# ESP32-S31 register map
Vendor: ESPRESSIF SYSTEMS (SHANGHAI) CO., LTD.; Series: ESP32 S-Series; File version: 1
CPU: RV32IMAFC r0p0, little endian, no MPU, FPU, 0 interrupt priority bits
Address unit: 32 bits
Registers are 32-bit, read-write, reset 0x0 unless marked. A register's access mark holds for its fields unless they carry their own. Offsets are from the block's base; [hi:lo] are bit positions.

## USB_OTG_HS (part 1 of 5) — USB_OTG_HS Peripheral
Base 0x20300000
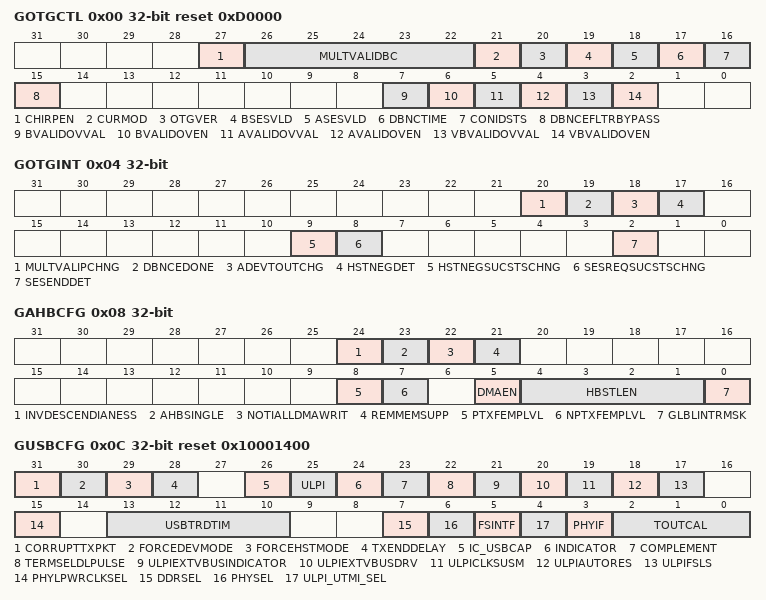
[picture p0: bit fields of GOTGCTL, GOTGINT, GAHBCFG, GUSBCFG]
0x00 GOTGCTL access per field reset 0xD0000 — The OTG Control and Status register controls the behavior and reflects the status of the OTG function of the controller.
  [27] CHIRPEN rw — Mode: Device Only This bit when programmed to 1'b1 results in the core asserting chirp_on before sending an actual Chirp K signal on USB. This bit is present only if OTG_BC_SUPPORT = 1.If OTG_BC_SUPPORT!=1, this bit is a reserved bit. Do not set this bit when core is operating in HSIC mode because HSIC always operates at High Speed and High speed chirp is not used
  [26:22] MULTVALIDBC ro — Mode: Host and Device Multi Valued ID pin (MultValIdBC) Battery Charger ACA inputs in the following order: - Bit 26: rid_float. - Bit 25: rid_gnd - Bit 24: rid_a - Bit 23: rid_b - Bit 22: rid_c
  [21] CURMOD ro — Current Mode of Operation (CurMod) Mode: Host and Device Indicates the current mode. - 1'b0: Device mode - 1'b1: Host mode Reset: - 1'b1 in Host-only mode (OTG_MODE=5 or 6) - 1'b0 in all other configurations Note: The reset value of this register field can be read only after the PHY clock is stable, or if IDDIG_FILTER is enabled, wait for the filter timer to expire to read the correct reset value which ever event is later.
  [20] OTGVER rw — OTG Version (OTGVer) Indicates the OTG revision. - 1'b0: OTG Version 1.3. In this version the core supports Data line pulsing and VBus pulsing for SRP. - 1'b1: OTG Version 2.0. In this version the core supports only Data line pulsing for SRP.
  [19] BSESVLD ro — Mode: Device only B-Session Valid (BSesVld) Indicates the Device mode transceiver status. - 1'b0: B-session is not valid. - 1'b1: B-session is valid. In OTG mode, you can use this bit to determine if the device is connected or disconnected. Note: - If you do not enable OTG features (such as SRP and HNP), the read reset value will be 1.The vbus assigns the values internally for non- SRP or non-HNP configurations. - In case of OTG_MODE=0, the reset value of this bit is 1'b0. - The reset value of this register field can be read only after the PHY clock is stable, or if IDDIG_FILTER is enabled, wait for the filter timer to expire to read the correct reset value which ever event is later.
  [18] ASESVLD ro — Mode: Host only A-Session Valid (ASesVld) Indicates the Host mode transceiver status. - 1'b0: A-session is not valid - 1'b1: A-session is valid Note: If you do not enabled OTG features (such as SRP and HNP), the read reset value will be 1. The vbus assigns the values internally for non-SRP or non-HNP configurations. In case of OTG_MODE=0, the reset value of this bit is 1'b0.
  [17] DBNCTIME ro — Mode: Host only Long/Short Debounce Time (DbncTime) Indicates the debounce time of a detected connection. - 1'b0: Long debounce time, used for physical connections (100 ms + 2.5 micro-sec) - 1'b1: Short debounce time, used for soft connections (2.5 micro-sec)
  [16] CONIDSTS ro — Mode: Host and Device Connector ID Status (ConIDSts) Indicates the connector ID status on a connect event. - 1'b0: The core is in A-Device mode. - 1'b1: The core is in B-Device mode. Note: The reset value of this register field can be read only after the PHY clock is stable, or if IDDIG_FILTER is enabled, wait for the filter timer to expire to read the correct reset value which ever event is later. Reset: - 1'b0: in host only mode (OTG_MODE = 5 or 6) - 1'b1: in all other configurations
  [15] DBNCEFLTRBYPASS rw — Mode: Host and Device Debounce Filter Bypass Bypass Debounce filters for avalid, bvalid, vbusvalid, sessend, iddig signals when enabled. - 1'b0: Disabled - 1'b1: Enabled Note: This register bit is valid only when debounce filters are present in core.
  [7] BVALIDOVVAL rw — Mode: Device only B-Peripheral Session Valid OverrideValue (BvalidOvVal) This bit is used to set Override value for Bvalid signal when GOTGCTL.BvalidOvEn is set. - 1'b0 : Bvalid value is 1'b0 when GOTGCTL.BvalidOvEn =1 - 1'b1 : Bvalid value is 1'b1 when GOTGCTL.BvalidOvEn =1
  [6] BVALIDOVEN rw — Mode: Device only B-Peripheral Session Valid Override Value (BvalidOvEn) This bit is used to enable/disable the software to override the Bvalid signal using the GOTGCTL.BvalidOvVal. - 1'b1 : Internally Bvalid received from the PHY is overridden with GOTGCTL.BvalidOvVal. - 1'b0 : Override is disabled and bvalid signal from the respective PHY selected is used internally by the force
  [5] AVALIDOVVAL rw — Mode: Host only A-Peripheral Session Valid OverrideValue (AvalidOvVal) This bit is used to set Override value for Avalid signal when GOTGCTL.AvalidOvEn is set. - 1'b0 : Avalid value is 1'b0 when GOTGCTL.AvalidOvEn =1 - 1'b1 : Avalid value is 1'b1 when GOTGCTL.AvalidOvEn =1
  [4] AVALIDOVEN rw — Mode: Host only A-Peripheral Session Valid Override Enable (AvalidOvEn) This bit is used to enable/disable the software to override the Avalid signal using the GOTGCTL.AvalidOvVal. - 1'b1: Internally Avalid received from the PHY is overridden with GOTGCTL.AvalidOvVal. - 1'b0: Override is disabled and avalid signal from the respective PHY selected is used internally by the core
  [3] VBVALIDOVVAL rw — Mode: Host only VBUS Valid OverrideValue (VbvalidOvVal) This bit is used to set Override value for vbusvalid signal when GOTGCTL.VbvalidOvEn is set. - 1'b0 : vbusvalid value is 1'b0 when GOTGCTL.VbvalidOvEn =1 - 1'b1 : vbusvalid value is 1'b1 when GOTGCTL.VbvalidOvEn =1
  [2] VBVALIDOVEN rw — Mode: Host only VBUS Valid Override Enable (VbvalidOvEn) This bit is used to enable/disable the software to override the Bvalid signal using the GOTGCTL.VbvalidOvVal. - 1'b1 : Internally Bvalid received from the PHY is overridden with GOTGCTL.VbvalidOvVal. - 1'b0 : Override is disabled and bvalid signal from the respective PHY selected is used internally by the controller.
0x04 GOTGINT — The application reads this register whenever there is an OTG interrupt and clears the bits in this register to clear the OTG interrupt.
  [20] MULTVALIPCHNG — This bit when set indicates that there is a change in the value of at least one ACA pin value. This bit is present only if OTG_BC_SUPPORT=1, otherwise it is reserved.
  [19] DBNCEDONE — Mode: Host only Debounce Done (DbnceDone) The core sets this bit when the debounce is completed after the device connect. The application can start driving USB reset after seeing this interrupt. This bit is only valid when the HNP Capable or SRP Capable bit is SET in the Core USB Configuration register (GUSBCFG.HNPCap or GUSBCFG.SRPCap, respectively). This bit can be set only by the core and the application must write 1 to clear it.
  [18] ADEVTOUTCHG — Mode: Host and Device A-Device Timeout Change (ADevTOUTChg) The core sets this bit to indicate that the A-device has timed out while waiting for the B-device to connect.This bit can be set only by the core and the application must write 1 to clear it.
  [17] HSTNEGDET — Mode:Host and Device Host Negotiation Detected (HstNegDet) The core sets this bit when it detects a host negotiation request on the USB. This bit can be set only by the core and the application must write 1 to clear it.
  [9] HSTNEGSUCSTSCHNG — Mode: Host and Device Host Negotiation Success Status Change (HstNegSucStsChng) The core sets this bit on the success or failure of a USB host negotiation request. The application must read the Host Negotiation Success bit of the OTG Control and Status register (GOTGCTL.HstNegScs) to check for success or failure. This bit can be set only by the core and the application must write 1 to clear it.
  [8] SESREQSUCSTSCHNG — Mode: Host and Device Session Request Success Status Change (SesReqSucStsChng) The core sets this bit on the success or failure of a session request. The application must read the Session Request Success bit in the OTG Control and Status register (GOTGCTL.SesReqScs) to check for success or failure. This bit can be set only by the core and the application must write 1 to clear it.
  [2] SESENDDET — Mode: Host and Device Session End Detected (SesEndDet) The controller sets this bit when the utmiotg_bvalid signal is deasserted. This bit can be set only by the core and the application must write 1 to clear it.
0x08 GAHBCFG — This register can be used to configure the core after power-on or a change in mode. This register mainly contains AHB system-related configuration parameters. Do not change this register after the initial programming. The application must program this register before starting any transactions on either the AHB or the USB.
  [24] INVDESCENDIANESS — Mode: Host and Device Invert Descriptor Endianess (InvDescEndianess) - 1'b0: Descriptor Endianness is same as AHB Master Endianness. - 1'b1: -- If the AHB Master endianness is Big Endian, the Descriptor Endianness is Little Endian. -- If the AHB Master endianness is Little Endian, the Descriptor Endianness is Big Endian.
  [23] AHBSINGLE — Mode: Host and Device AHB Single Support (AHBSingle) This bit when programmed supports Single transfers for the remaining data in a transfer when the core is operating in DMA mode. - 1'b0: The remaining data in the transfer is sent using INCR burst size. - 1'b1: The remaining data in the transfer is sent using Single burst size. Note: If this feature is enabled, the AHB RETRY and SPLIT transfers still have INCR burst type. Enable this feature when the AHB Slave connected to the core does not support INCR burst (and when Split, and Retry transactions are not being used in the bus).
  [22] NOTIALLDMAWRIT — Mode: Host and Device Notify All DMA Write Transactions (NotiAllDmaWrit) This bit is programmed to enable the System DMA Done functionality for all the DMA write Transactions corresponding to the Channel/Endpoint. This bit is valid only when GAHBCFG.RemMemSupp is set to 1. - GAHBCFG.NotiAllDmaWrit = 1 The core asserts int_dma_req for all the DMA write transactions on the AHB interface along with int_dma_done, chep_last_transact and chep_number signal informations. The core waits for sys_dma_done signal for all the DMA write transactions in order to complete the transfer of a particular Channel/Endpoint. - GAHBCFG.NotiAllDmaWrit = 0 The core asserts int_dma_req signal only for the last transaction of DMA write transfer corresponding to a particular Channel/Endpoint. Similarly, the core waits for sys_dma_done signal only for that transaction of DMA write to complete the transfer of a particular Channel/Endpoint.
  [21] REMMEMSUPP — Mode: Host and Device Remote Memory Support (RemMemSupp) This bit is programmed to enable the functionality to wait for the system DMA Done Signal for the DMA Write Transfers. - GAHBCFG.RemMemSupp=1 The int_dma_req output signal is asserted when the DMA starts write transfer to the external memory. When the core is done with the Transfers it asserts int_dma_done signal to flag the completion of DMA writes from the controller. The core then waits for sys_dma_done signal from the system to proceed further and complete the Data Transfer corresponding to a particular Channel/Endpoint. - GAHBCFG.RemMemSupp=0 The int_dma_req and int_dma_done signals are not asserted and the core proceeds with the assertion of the XferComp interrupt as soon as the DMA write transfer is done at the Core Boundary and it does not wait for the sys_dma_done signal to complete the DATA transfers.
  [8] PTXFEMPLVL — Mode: Host only Periodic TxFIFO Empty Level (PTxFEmpLvl) Indicates when the Periodic TxFIFO Empty Interrupt bit in the Core Interrupt register (GINTSTS.PTxFEmp) is triggered. This bit is used only in Slave mode. - 1'b0: GINTSTS.PTxFEmp interrupt indicates that the Periodic TxFIFO is half empty - 1'b1: GINTSTS.PTxFEmp interrupt indicates that the Periodic TxFIFO is completely empty
  [7] NPTXFEMPLVL — Mode: Host and device Non-Periodic TxFIFO Empty Level (NPTxFEmpLvl) This bit is used only in Slave mode. In host mode and with Shared FIFO with device mode, this bit indicates when the Non-Periodic TxFIFO Empty Interrupt bit in the Core Interrupt register (GINTSTS.NPTxFEmp) is triggered. With dedicated FIFO in device mode, this bit indicates when IN endpoint Transmit FIFO empty interrupt (DIEPINTn.TxFEmp) is triggered. Host mode and with Shared FIFO with device mode: - 1'b0: GINTSTS.NPTxFEmp interrupt indicates that the Non-Periodic TxFIFO is half empty - 1'b1: GINTSTS.NPTxFEmp interrupt indicates that the Non-Periodic TxFIFO is completely empty Dedicated FIFO in device mode: - 1'b0: DIEPINTn.TxFEmp interrupt indicates that the IN Endpoint TxFIFO is half empty - 1'b1: DIEPINTn.TxFEmp interrupt indicates that the IN Endpoint TxFIFO is completely empty
  [5] DMAEN — Mode: Host and device DMA Enable (DMAEn) This bit is always 0 when Slave-Only mode has been selected. Reset: 1'b0
  [4:1] HBSTLEN — Mode: Host and device Burst Length/Type (HBstLen) This field is used in both External and Internal DMA modes. In External DMA mode, these bits appear on dma_burst[3:0] ports, which can be used by an external wrapper to interface the External DMA Controller interface to Synopsys DW_ahb_dmac or ARM PrimeCell. External DMA Mode defines the DMA burst length in terms of 32-bit words: - 4'b0000: 1 word - 4'b0001: 4 words - 4'b0010: 8 words - 4'b0011: 16 words - 4'b0100: 32 words - 4'b0101: 64 words - 4'b0110: 128 words - 4'b0111: 256 words - Others: Reserved Internal DMA Mode AHB Master burst type: - 4'b0000 Single - 4'b0001 INCR - 4'b0011 INCR4 - 4'b0101 INCR8 - 4'b0111 INCR16 - Others: Reserved
  [0] GLBLINTRMSK — Mode: Host and device Global Interrupt Mask (GlblIntrMsk) The application uses this bit to mask or unmask the interrupt line assertion to itself. Irrespective of this bit's setting, the interrupt status registers are updated by the controller.
0x0C GUSBCFG access per field reset 0x10001400 — This register can be used to configure the core after power-on or when changing to Host mode or Device mode. It contains USB and USB-PHY related configuration parameters. The application must program this register before starting any transactions on either the AHB or the USB. If you are using the HSIC interface, HSIC PHY must be in reset while programming this register. Do not make changes to this register after the initial programming.
  [31] CORRUPTTXPKT rw — Mode: Host and device Corrupt Tx packet (CorruptTxPkt) This bit is for debug purposes only. Never Set this bit to 1. The application must always write 1'b0 to this bit.
  [30] FORCEDEVMODE rw — Mode:Host and device Force Device Mode (ForceDevMode) Writing a 1 to this bit forces the controller to device mode irrespective of utmiotg_iddig input pin. - 1'b0 : Normal Mode. - 1'b1 : Force Device Mode. After setting the force bit, the application must wait at least 25 ms before the change to take effect. When the simulation is in scale down mode, waiting for 500 micro sec is sufficient. This bit is valid only when OTG_MODE = 0, 1 or 2. In all other cases, this bit reads 0.
  [29] FORCEHSTMODE rw — Mode: Host and device Force Host Mode (ForceHstMode) Writing a 1 to this bit forces the core to host mode irrespective of utmiotg_iddig input pin. - 1'b0 : Normal Mode. - 1'b1 : Force Host Mode. After setting the force bit, the application must wait at least 25 ms before the change to take effect. When the simulation is in scale down mode, waiting for 500 micro sec is sufficient. This bit is valid only when OTG_MODE = 0, 1 or 2. In all other cases, this bit reads 0.
  [28] TXENDDELAY rw — Mode: Device only Tx End Delay (TxEndDelay) Setting this bit to 1'b1 enables the controller to follow the TxEndDelay timings as per UTMI+ specification 1.05 section 4.1.5 for opmode signal during remote wakeup. - 1'b0 : Normal Mode. - 1'b1 : Tx End delay. The default value of this field is 1'b1 and it is not recommended to program it to 1'b0. The option to set it to 1'b0 (Normal Mode) is present only for debug purpose.
  [26] IC_USBCAP ro — Mode: Host and Device IC_USB-Capable (IC_USBCap) The application uses this bit to control the core's IC_USB capabilities. - 1'b0: IC_USB PHY Interface is not selected. - 1'b1: IC_USB PHY Interface is selected. This bit is writable only if OTG_ENABLE_IC_USB=1 and OTG_FSPHY_INTERFACE!=0. The reset value depends on the configuration parameter OTG_SELECT_IC_USB when OTG_ENABLE_IC_USB = 1. In all other cases, this bit is set to 1'b0 and the bit is read only.
  [25] ULPI rw — Mode: Host only ULPI Interface Protect Disable Controls circuitry built into the PHY for protecting the ULPI interface when the link tri-states STP and data. Any pull-ups or pull-downs employed by this feature can be disabled. For more information, refer to the ULPI Specification. - 1'b0: Enables the interface protect circuit - 1'b1: Disables the interface protect circuit
  [24] INDICATOR rw — Mode: Host only Indicator Pass Through Controls wether the Complement Output is qualified with the Internal Vbus Valid comparator before being used in the Vbus State in the RX CMD. For more information, refer to the ULPI Specification. - 1'b0: Complement Output signal is qualified with the Internal VbusValid comparator. - 1'b1: Complement Output signal is not qualified with the Internal VbusValid comparator. This bit is reserved and read-only when OTG_HSPHY_INTERFACE is set to 0 or 1.
  [23] COMPLEMENT rw — Mode: Host only Indicator Complement Controls the PHY to invert the ExternalVbusIndicator input signal, generating the Complement Output. For more information, refer to the ULPI Specification. - 1'b0: PHY does not invert ExternalVbusIndicator signal - 1'b1: PHY does invert ExternalVbusIndicator signal This bit is reserved and read-only when OTG_HSPHY_INTERFACE is set to 0 or 1.
  [22] TERMSELDLPULSE rw — Mode: Device only TermSel DLine Pulsing Selection (TermSelDLPulse) This bit selects utmi_termselect to drive data line pulse during SRP. - 1'b0: Data line pulsing using utmi_txvalid (Default). - 1'b1: Data line pulsing using utmi_termsel.
  [21] ULPIEXTVBUSINDICATOR rw — Mode: Host only ULPI External VBUS Indicator (ULPIExtVbusIndicator) This bit indicates to the ULPI PHY to use an external VBUS overcurrent indicator. - 1'b0: PHY uses internal VBUS valid comparator. - 1'b1: PHY uses external VBUS valid comparator.
  [20] ULPIEXTVBUSDRV rw — Mode: Host only ULPI External VBUS Drive (ULPIExtVbusDrv) This bit selects between internal or external supply to drive 5V on VBUS, in ULPI PHY. - 1'b0: PHY drives VBUS using internal charge pump (Default). - 1'b1: PHY drives VBUS using external supply.
  [19] ULPICLKSUSM rw — Mode: Host and Device ULPI Clock SuspendM (ULPIClkSusM) This bit sets the ClockSuspendM bit in the Interface Control register on the ULPI PHY. This bit applies only in serial or carkit modes. - 1'b0: PHY powers down internal clock during suspend. - 1'b1: PHY does not power down internal clock.
  [18] ULPIAUTORES rw — Mode: Host and Device ULPI Auto Resume (ULPIAutoRes) This bit sets the AutoResume bit in the Interface Control register on the ULPI PHY. - 1'b0: PHY does not use AutoResume feature. - 1'b1: PHY uses AutoResume feature.
  [17] ULPIFSLS rw — Mode: Host and Device ULPI FS/LS Select (ULPIFsLs) The application uses this bit to select the FS/LS serial interface for the ULPI PHY. This bit is valid only when the FS serial transceiver is selected on the ULPI PHY. - 1'b0: ULPI interface - 1'b1: ULPI FS/LS serial interface Note: Before setting this bit, the application needs to ensure that GUSBCFG.ULPI_UTMI_SEL = 1'b1.
  [15] PHYLPWRCLKSEL rw — PHY Low-Power Clock Select (PhyLPwrClkSel) Mode: Host and Device Selects either 480-MHz or 48-MHz (low-power) PHY mode. In FS and LS modes, the PHY can usually operate on a 48-MHz clock to save power. - 1'b0: 480-MHz Internal PLL clock - 1'b1: 48-MHz External Clock In 480 MHz mode, the UTMI interface operates at either 60 or 30-MHz, depending upon whether 8- or 16-bit data width is selected. In 48-MHz mode, the UTMI interface operates at 48 MHz in FS mode and at either 48 or 6 MHz in LS mode (depending on the PHY vendor). This bit drives the utmi_fsls_low_power core output signal, and is valid only for UTMI+ PHYs.
  [13:10] USBTRDTIM rw — Mode: Device only USB Turnaround Time (USBTrdTim) Sets the turnaround time in PHY clocks. Specifies the response time for a MAC request to the Packet FIFO Controller (PFC) to fetch data from the DFIFO (SPRAM). This must be programmed to - 4'h5 : When the MAC interface is 16-bit UTMI+ - 4'h9 : When the MAC interface is 8-bit UTMI+ Note:Refer to Programming Guide Section Choosing the Value of GUSBCFG.USBTrdTim for the turnaround time calculation. During the AHB Clock Frequency selection, it is recommended to consider mis-sampling into account for USBTrdTim. USB turnaround time is critical for certification where long cables and 5-Hubs are used. If you need the AHB to run at less than 30 MHz (or less than 42MHz when operating in 16-bit UTMI mode in HS speed), and if USB turnaround time is not critical, these bits can be programmed to a larger value.
  [7] DDRSEL rw — Mode: Host and Device ULPI DDR Select (DDRSel) The application uses this bit to select a Single Data Rate (SDR) or Double Data Rate (DDR) or ULPI interface. - 1'b0: Single Data Rate ULPI Interface, with 8-bit-wide data bus - 1'b1: Double Data Rate ULPI Interface, with 4-bit-wide data bus
  [6] PHYSEL rw — PHYSel Mode: Host and Device USB 2.0 High-Speed PHY or USB 1.1 Full-Speed Serial Transceiver Select (PHYSel) The application uses this bit to select either a high-speed UTMI+ or ULPI PHY, or a full-speed transceiver. - 1'b0: USB 2.0 high-speed UTMI+ or ULPI PHY - 1'b1: USB 1.1 full-speed serial transceiver If a USB 1.1 Full-Speed Serial Transceiver interface was not selected in, this bit is always 0, with Write Only access. If a high-speed PHY interface was not selected in, this bit is always 1, with Write Only access. If both interface types were selected (parameters have non-zero values), the application uses this bit to select which interface is active, and access is Read and Write.
  [5] FSINTF rw — Mode: Host and Device Full-Speed Serial Interface Select (FSIntf) The application uses this bit to select either a unidirectional or bidirectional USB 1.1 full-speed serial transceiver interface. - 1'b0: 6-pin unidirectional full-speed serial interface - 1'b1: 3-pin bidirectional full-speed serial interface If a USB 1.1 Full-Speed Serial Transceiver interface was not selected, this bit is always 0, with Write Only access. If a USB 1.1 FS interface was selected, Then the application can Set this bit to select between the 3- and 6-pin interfaces, and access is Read and Write. Note: For supporting the new 4-pin bi-directional interface, you need to select 6-pin unidirectional FS serial mode, and add an external control to convert it to a 4-pin interface.
  [4] ULPI_UTMI_SEL rw — Mode: Host and Device ULPI or UTMI+ Select (ULPI_UTMI_Sel) The application uses this bit to select either a UTMI+ interface or ULPI Interface. - 1'b0: UTMI+ Interface - 1'b1: ULPI Interface
  [3] PHYIF rw — Mode: Host and Device PHY Interface (PHYIf) The application uses this bit to configure the core to support a UTMI+ PHY with an 8- or 16-bit interface. When a ULPI PHY is chosen, this must be Set to 8-bit mode. - 1'b0: 8 bits - 1'b1: 16 bits This bit is writable only If UTMI+ and ULPI were selected. Otherwise, this bit returns the value for the power-on interface selected during configuration.
  [2:0] TOUTCAL rw — Mode: Host and Device HS/FS Timeout Calibration (TOutCal) The number of PHY clocks that the application programs in this field is added to the high-speed/full-speed interpacket timeout duration in the core to account for any additional delays introduced by the PHY. This can be required, because the delay introduced by the PHY in generating the linestate condition can vary from one PHY to another. The USB standard timeout value for high-speed operation is 736 to 816 (inclusive) bit times. The USB standard timeout value for full-speed operation is 16 to 18 (inclusive) bit times. The application must program this field based on the speed of enumeration. The number of bit times added per PHY clock are as follows: High-speed operation: - One 30-MHz PHY clock = 16 bit times - One 60-MHz PHY clock = 8 bit times Full-speed operation: - One 30-MHz PHY clock = 0.4 bit times - One 60-MHz PHY clock = 0.2 bit times - One 48-MHz PHY clock = 0.25 bit times
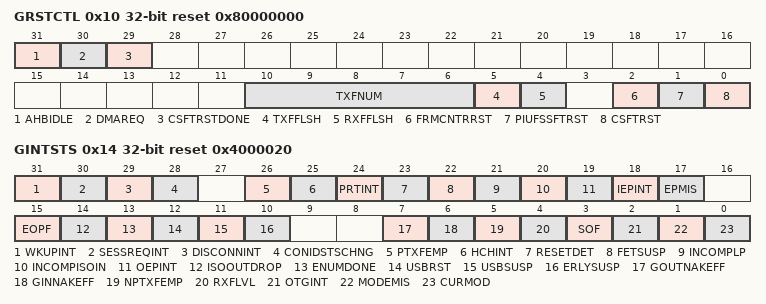
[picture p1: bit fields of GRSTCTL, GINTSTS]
0x10 GRSTCTL access per field reset 0x80000000 — The application uses this register to reset various hardware features inside the controller.
  [31] AHBIDLE ro — Mode: Host and Device AHB Master Idle (AHBIdle) Indicates that the AHB Master State Machine is in the IDLE condition.
  [30] DMAREQ ro — Mode: Host and Device DMA Request Signal (DMAReq) Indicates that the DMA request is in progress. Used for debug.
  [29] CSFTRSTDONE rw — Mode: Host and Device Core Soft Reset Done (CSftRstDone) The core sets this bit when all the necessary logic is reset in the core.This bit is cleared by the application along with GRSTCTL.CSftRst (bit 0)
  [10:6] TXFNUM rw — Mode: Host and Device TxFIFO Number (TxFNum) This is the FIFO number that must be flushed using the TxFIFO Flush bit. This field must not be changed until the core clears the TxFIFO Flush bit. - 5'h0: -- Non-periodic TxFIFO flush in Host mode -- Non-periodic TxFIFO flush in device mode when in shared FIFO operation -- Tx FIFO 0 flush in device mode when in dedicated FIFO mode - 5'h1: -- Periodic TxFIFO flush in Host mode -- Periodic TxFIFO 1 flush in Device mode when in shared FIFO operation -- TXFIFO 1 flush in device mode when in dedicated FIFO mode - 5'h2: -- Periodic TxFIFO 2 flush in Device mode when in shared FIFO operation -- TXFIFO 2 flush in device mode when in dedicated FIFO mode ... - 5'hF -- Periodic TxFIFO 15 flush in Device mode when in shared FIFO operation -- TXFIFO 15 flush in device mode when in dedicated FIFO mode - 5'h10: Flush all the transmit FIFOs in device or host mode
  [5] TXFFLSH rw — Mode: Host and Device TxFIFO Flush (TxFFlsh) This bit selectively flushes a single or all transmit FIFOs, but cannot do so If the core is in the midst of a transaction. The application must write this bit only after checking that the core is neither writing to the TxFIFO nor reading from the TxFIFO. Verify using these registers: - ReadNAK Effective Interrupt ensures the core is not reading from the FIFO - WriteGRSTCTL.AHBIdle ensures the core is not writing anything to the FIFO. Flushing is normally recommended when FIFOs are reconfigured or when switching between Shared FIFO and Dedicated Transmit FIFO operation. FIFO flushing is also recommended during device endpoint disable. The application must wait until the core clears this bit before performing any operations. This bit takes eight clocks to clear, using the slower clock of phy_clk or hclk.
  [4] RXFFLSH rw — Mode: Host and Device RxFIFO Flush (RxFFlsh) The application can flush the entire RxFIFO using this bit, but must first ensure that the core is not in the middle of a transaction. The application must only write to this bit after checking that the controller is neither reading from the RxFIFO nor writing to the RxFIFO. The application must wait until the bit is cleared before performing any other operations. This bit requires eight clocks (slowest of PHY or AHB clock) to clear.
  [2] FRMCNTRRST rw — Mode: Host only Host Frame Counter Reset (FrmCntrRst) The application writes this bit to reset the (micro)Frame number counter inside the core. When the (micro)Frame counter is reset, the subsequent SOF sent out by the core has a (micro)Frame number of 0. When application writes 1 to the bit, it might not be able to read back the value as it gets cleared by the core in a few clock cycles.
  [1] PIUFSSFTRST rw — Mode: Host and Device PIU FS Dedicated Controller Soft Reset (PIUFSSftRst) Resets the PIU FS Dedicated Controller All module state machines in FS Dedicated Controller of PIU are reset to the IDLE state. Used to reset the FS Dedicated controller in PIU in case of any PHY Errors like Loss of activity or Babble Error resulting in the PHY remaining in RX state for more than one frame boundary. This is a self clearing bit and core clears this bit after all the necessary logic is reset in the core.
  [0] CSFTRST rw — Mode: Host and Device Core Soft Reset (CSftRst) Resets the hclk and phy_clock domains as follows: - Clears the interrupts and all the CSR registers except the following register bits: -- PCGCCTL.RstPdwnModule -- PCGCCTL.GateHclk -- PCGCCTL.PwrClmp -- PCGCCTL.StopPPhyLPwrClkSelclk -- GUSBCFG.ForceDevMode -- GUSBCFG.ForceHstMode -- GUSBCFG.PhyLPwrClkSel -- GUSBCFG.DDRSel -- GUSBCFG.PHYSel -- GUSBCFG.FSIntf -- GUSBCFG.ULPI_UTMI_Sel -- GUSBCFG.PHYIf -- GUSBCFG.TxEndDelay -- GUSBCFG.TermSelDLPulse -- GUSBCFG.ULPIClkSusM -- GUSBCFG.ULPIAutoRes -- GUSBCFG.ULPIFsLs -- GGPIO -- GPWRDN -- GADPCTL -- HCFG.FSLSPclkSel -- DCFG.DevSpd -- DCTL.SftDiscon - All module state machines - All module state machines (except the AHB Slave Unit) are reset to the IDLE state, and all the transmit FIFOs and the receive FIFO are flushed. - Any transactions on the AHB Master are terminated as soon as possible, after gracefully completing the last data phase of an AHB transfer. Any transactions on the USB are terminated immediately. - When Hibernation or ADP feature is enabled, the PMU module is not reset by the Core Soft Reset. The application can write to this bit any time it wants to reset the core. The application must clear this bit after checking the bit 29 of this register (Core Soft Reset Done). Software must also must check that bit 31 of this register is 1 (AHB Master is IDLE) before starting any operation. Typically software reset is used during software development and also when you dynamically change the PHY selection bits in the USB configuration registers listed above. When you change the PHY, the corresponding clock for the PHY is selected and used in the PHY domain. Once a new clock is selected, the PHY domain has to be reset for proper operation.
0x14 GINTSTS access per field reset 0x4000020 — This register interrupts the application for system-level events in the current mode (Device mode or Host mode). Some of the bits in this register are valid only in Host mode, while others are valid in Device mode only. This register also indicates the current mode. To clear the interrupt status bits of type R_SS_WC, the application must write 1'b1 to the bit. The FIFO status interrupts are read only; once software reads from or writes to the FIFO while servicing these interrupts, FIFO interrupt conditions are cleared automatically. The application must clear the GINTSTS register at initialization before unmasking the interrupt bit to avoid any interrupts generated prior to initialization. Note: Read the reset value of GINTSTS.CurMod only after the following conditions: - If IDDIG_FILTER is disabled, read only after PHY clock is stable. - If IDDIG_FILTER is enabled, read only after the filter timer expires.
  [31] WKUPINT rw — Mode: Host and Device Resume/Remote Wakeup Detected Interrupt (WkUpInt) Wakeup Interrupt during Suspend(L2) or LPM(L1) state. - During Suspend(L2): -- Device Mode: This interrupt is asserted only when Host Initiated Resume is detected on USB. -- Host Mode: This interrupt is asserted only when Device Initiated Remote Wakeup is detected on USB. For more information, see 'Partial Power-Down and Clock Gating Programming Model' in the Programming Guide. - During LPM(L1): -- Device Mode: This interrupt is asserted for either Host Initiated Resume or Device Initiated Remote Wakeup on USB. -- Host Mode: This interrupt is asserted for either Host Initiated Resume or Device Initiated Remote Wakeup on USB. For more information, see 'LPM Entry and Exit Programming Model' in the Programming Guide.
  [30] SESSREQINT rw — Mode: Host and Device Session Request/New Session Detected Interrupt (SessReqInt) In Host mode, this interrupt is asserted when a session request is detected from the device. In Host mode, this interrupt is asserted when a session request is detected from the device. In Device mode, this interrupt is asserted when the utmisrp_bvalid signal goes high. For more information on how to use this interrupt, see 'Partial Power-Down and Clock Gating Programming Model' in the Programming Guide.
  [29] DISCONNINT rw — Mode: Host only Disconnect Detected Interrupt (DisconnInt) Asserted when a device disconnect is detected.
  [28] CONIDSTSCHNG rw — Mode: Host and Device Connector ID Status Change (ConIDStsChng) The core sets this bit when there is a change in connector ID status.
  [26] PTXFEMP ro — Mode: Host only Periodic TxFIFO Empty (PTxFEmp) This interrupt is asserted when the Periodic Transmit FIFO is either half or completely empty and there is space for at least one entry to be written in the Periodic Request Queue. The half or completely empty status is determined by the Periodic TxFIFO Empty Level bit in the Core AHB Configuration register (GAHBCFG.PTxFEmpLvl).
  [25] HCHINT ro — Mode: Host only Host Channels Interrupt (HChInt) The core sets this bit to indicate that an interrupt is pending on one of the channels of the core (in Host mode). The application must read the Host All Channels Interrupt (HAINT) register to determine the exact number of the channel on which the interrupt occurred, and Then read the corresponding Host Channel-n Interrupt (HCINTn) register to determine the exact cause of the interrupt. The application must clear the appropriate status bit in the HCINTn register to clear this bit.
  [24] PRTINT ro — Mode: Host only Host Port Interrupt (PrtInt) The core sets this bit to indicate a change in port status of one of the controller ports in Host mode. The application must read the Host Port Control and Status (HPRT) register to determine the exact event that caused this interrupt. The application must clear the appropriate status bit in the Host Port Control and Status register to clear this bit.
  [23] RESETDET rw — Mode: Device only Reset detected Interrupt (ResetDet) In Device mode, this interrupt is asserted when a reset is detected on the USB in partial power-down mode when the device is in Suspend. In Host mode, this interrupt is not asserted.
  [22] FETSUSP rw — Mode: Device only Data Fetch Suspended (FetSusp) This interrupt is valid only in DMA mode. This interrupt indicates that the core has stopped fetching data. For IN endpoints due to the unavailability of TxFIFO space or Request Queue space. This interrupt is used by the application for an endpoint mismatch algorithm. For example, after detecting an endpoint mismatch, the application: - Sets a Global non-periodic IN NAK handshake - Disables IN endpoints - Flushes the FIFO - Determines the token sequence from the IN Token Sequence Learning Queue - Re-enables the endpoints - Clears the Global non-periodic IN NAK handshake If the Global non-periodic IN NAK is cleared, the core has not yet fetched data for the IN endpoint, and the IN token is received. The core generates an 'IN token received when FIFO empty' interrupt. It then sends the host a NAK response. To avoid this scenario, the application can check the GINTSTS.FetSusp interrupt, which ensures that the FIFO is full before clearing a Global NAK handshake. Alternatively, the application can mask the IN token received when FIFO empty interrupt when clearing a Global IN NAK handshake.
  [21] INCOMPLP rw — Incomplete Periodic Transfer (incomplP) Mode: Host only In Host mode, the core sets this interrupt bit when there are incomplete periodic transactions still pending which are scheduled for the current microframe. Incomplete Isochronous OUT Transfer (incompISOOUT) Mode: Device only The Device mode, the core sets this interrupt to indicate that there is at least one isochronous OUT endpoint on which the transfer is not completed in the current microframe. This interrupt is asserted along with the End of Periodic Frame Interrupt (EOPF) bit in this register.
  [20] INCOMPISOIN rw — Mode: Device only Incomplete Isochronous IN Transfer (incompISOIN) The core sets this interrupt to indicate that there is at least one isochronous IN endpoint on which the transfer is not completed in the current microframe. This interrupt is asserted along with the End of Periodic Frame Interrupt (EOPF) bit in this register. Note: This interrupt is not asserted in Scatter/Gather DMA mode.
  [19] OEPINT ro — Mode: Device only OUT Endpoints Interrupt (OEPInt) The controller sets this bit to indicate that an interrupt is pending on one of the OUT endpoints of the core (in Device mode). The application must read the Device All Endpoints Interrupt (DAINT) register to determine the exact number of the OUT endpoint on which the interrupt occurred, and then read the corresponding Device OUT Endpoint-n Interrupt (DOEPINTn) register to determine the exact cause of the interrupt. The application must clear the appropriate status bit in the corresponding DOEPINTn register to clear this bit.
  [18] IEPINT ro — Mode: Device only IN Endpoints Interrupt (IEPInt) The core sets this bit to indicate that an interrupt is pending on one of the IN endpoints of the core (in Device mode). The application must read the Device All Endpoints Interrupt (DAINT) register to determine the exact number of the IN endpoint on Device IN Endpoint-n Interrupt (DIEPINTn) register to determine the exact cause of the interrupt. The application must clear the appropriate status bit in the corresponding DIEPINTn register to clear this bit.
  [17] EPMIS rw — Mode: Device only Endpoint Mismatch Interrupt (EPMis) Note: This interrupt is valid only in shared FIFO operation. Indicates that an IN token has been received for a non-periodic endpoint, but the data for another endpoint is present in the top of the Non-periodic Transmit FIFO and the IN endpoint mismatch count programmed by the application has expired.
  [15] EOPF rw — Mode: Device only End of Periodic Frame Interrupt (EOPF) Indicates that the period specified in the Periodic Frame Interval field of the Device Configuration register (DCFG.PerFrInt) has been reached in the current microframe. In case of Non-Ignore Frame Number Scatter/Gather (Descriptor DMA) mode, the controller internally handles the following scenarios based on EOPF: Read Flush: At the EOPF, the controller checks if there are any pending packets in the FIFO corresponding to the current (micro)Frame. - If there are any pending packets, then the controller initiates read flush, due to which the read pointer is updated to the starting location of the next micro-frame packet. - If there are no pending packets corresponding to the current (micro)Frame, the controller does not take any action. Write Flush: At the EOPF, if the controller is still fetching the current micro-frame data, then the controller stops pushing data into the TXFIFO but keeps fetching the complete packet from the System Memory. After completing the scheduled packet size fetch, the controller updates the Status Quadlet Fields (Transmit Status to BUFFLUSH) and closes the Descriptor. During the descriptor close, the controller initiates write flush, due to which the write pointer is updated to the starting location of the next micro-frame packet. Because the controller stops pushing the packet to the TxFIFO after EOPF, to bring the write pointer to the starting location of the next micro-frame, write flush is done.
  [14] ISOOUTDROP rw — Mode: Device only Isochronous OUT Packet Dropped Interrupt (ISOOutDrop) The controller sets this bit when it fails to write an isochronous OUT packet into the RxFIFO because the RxFIFO does not have enough space to accommodate a maximum packet size packet for the isochronous OUT endpoint.
  [13] ENUMDONE rw — Mode: Device only Enumeration Done (EnumDone) The core sets this bit to indicate that speed enumeration is complete. The application must read the Device Status (DSTS) register to obtain the enumerated speed.
  [12] USBRST rw — Mode: Device only USB Reset (USBRst) The controller sets this bit to indicate that a reset is detected on the USB.
  [11] USBSUSP rw — Mode: Device only USB Suspend (USBSusp) The controller sets this bit to indicate that a suspend was detected on the USB. The controller enters the Suspended state when there is no activity on the linestate signal for an extended period of time.
  [10] ERLYSUSP rw — Mode: Device only Early Suspend (ErlySusp) The controller sets this bit to indicate that an Idle state has been detected on the USB for 3 ms.
  [7] GOUTNAKEFF ro — Mode: Device only Global OUT NAK Effective (GOUTNakEff) Indicates that the Set Global OUT NAK bit in the Device Control register (DCTL.SGOUTNak), Set by the application, has taken effect in the core. This bit can be cleared by writing the Clear Global OUT NAK bit in the Device Control register (DCTL.CGOUTNak).
  [6] GINNAKEFF ro — Mode: Device only Global IN Non-periodic NAK Effective (GINNakEff) Indicates that the Set Global Non-periodic IN NAK bit in the Device Control register (DCTL.SGNPInNak) set by the application, has taken effect in the core. That is, the core has sampled the Global IN NAK bit Set by the application. This bit can be cleared by clearing the Clear Global Non-periodic IN NAK bit in the Device Control register (DCTL.CGNPInNak). This interrupt does not necessarily mean that a NAK handshake is sent out on the USB. The STALL bit takes precedence over the NAK bit.
  [5] NPTXFEMP ro — Mode: Host and Device Non-periodic TxFIFO Empty (NPTxFEmp) This interrupt is asserted when the Non-periodic TxFIFO is either half or completely empty, and there is space for at least one Entry to be written to the Non-periodic Transmit Request Queue. The half or completely empty status is determined by the Non-periodic TxFIFO Empty Level bit in the Core AHB Configuration register (GAHBCFG.NPTxFEmpLvl). In host mode, the application can use GINTSTS.NPTxFEmp with the OTG_EN_DED_TX_FIFO parameter set to either 1 or 0. In device mode, the application uses GINTSTS.NPTxFEmp when OTG_EN_DED_TX_FIFO=0. When OTG_EN_DED_TX_FIFO=1, the application uses DIEPINTn.TxFEmp.
  [4] RXFLVL ro — Mode: Host and Device RxFIFO Non-Empty (RxFLvl) Indicates that there is at least one packet pending to be read from the RxFIFO.
  [3] SOF rw — Mode: Host and Device Start of (micro)Frame (Sof) In Host mode, the core sets this bit to indicate that an SOF (FS), micro-SOF (HS), or Keep-Alive (LS) is transmitted on the USB. The application must write a 1 to this bit to clear the interrupt. In Device mode, the controller sets this bit to indicate that an SOF token has been received on the USB. The application can read the Device Status register to get the current (micro)Frame number. This interrupt is seen only when the core is operating at either HS or FS. This bit can be set only by the core and the application must write 1 to clear it. Note: This register may return 1'b1 if read immediately after power-on reset. If the register bit reads 1'b1 immediately after power-on reset, it does not indicate that an SOF has been sent (in case of host mode) or SOF has been received (in case of device mode). The read value of this interrupt is valid only after a valid connection between host and device is established. If the bit is set after power on reset the application can clear the bit.
  [2] OTGINT ro — Mode: Host and Device OTG Interrupt (OTGInt) The controller sets this bit to indicate an OTG protocol event. The application must read the OTG Interrupt Status (GOTGINT) register to determine the exact event that caused this interrupt. The application must clear the appropriate status bit in the GOTGINT register to clear this bit.
  [1] MODEMIS rw — Mode: Host and Device Mode Mismatch Interrupt (ModeMis) The core sets this bit when the application is trying to access: - A Host mode register, when the controller is operating in Device mode - A Device mode register, when the controller is operating in Host mode The register access is completed on the AHB with an OKAY response, but is ignored by the controller internally and does not affect the operation of the controller. This bit can be set only by the core and the application must write 1 to clear it.
  [0] CURMOD ro — Mode: Host and Device Current Mode of Operation (CurMod) Indicates the current mode. - 1'b0: Device mode - 1'b1: Host mode Note: The reset value of this register field can be read only after the PHY clock is stable, or if IDDIG_FILTER is enabled, wait for the filter timer to expire to read the correct reset value which ever event is later.
